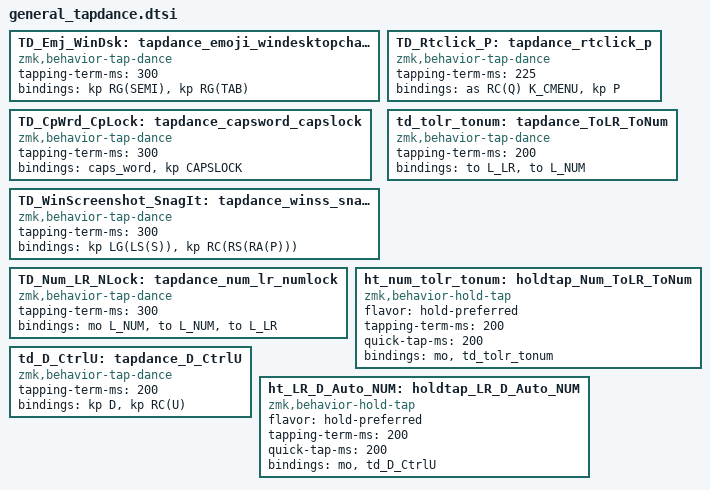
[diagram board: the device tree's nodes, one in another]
/*****************************************************************************************************
 *  TAP DANCE configurations
 *  for general cases
 *  [ ] macro-ify?
 *****************************************************************************************************/
#include <dt-bindings/zmk/keys.h>

// INCLUDE THIS inside Behaviors section of Keymap where other dependencies already pre-included

// 2024-04-16: label removed from ZMK v3

TD_Emj_WinDsk: tapdance_emoji_windesktopchange {
    compatible = "zmk,behavior-tap-dance";
    #binding-cells = <0>;
    tapping-term-ms = <300>;
    bindings = <&kp RG(SEMI)>, <&kp RG(TAB)>; // [1x] Win+; (Emoji pop-up)    [2x] Win+Tab (Windows desktops)
};

TD_CpWrd_CpLock: tapdance_capsword_capslock {
    compatible = "zmk,behavior-tap-dance";
    #binding-cells = <0>;
    tapping-term-ms = <300>;
    bindings = <&caps_word>, <&kp CAPSLOCK>;
};

/* Home/End: 2024-04-21 replaced with Hold/Tap instead of 2x-tap
TD_Hm_CtrlHm: tapdance_home_ctrlhome {
    compatible = "zmk,behavior-tap-dance";
    #binding-cells = <0>;
    tapping-term-ms = <300>;
    bindings = <&kp HOME>, <&kp RC(HOME)>;
};

TD_En_CtrlEn: tapdance_end_ctrlend {
    compatible = "zmk,behavior-tap-dance";
    #binding-cells = <0>;
    tapping-term-ms = <300>;
    bindings = <&kp END>, <&kp RC(END)>;
};
*/

TD_WinScreenshot_SnagIt: tapdance_winss_snagitss {
    compatible = "zmk,behavior-tap-dance";
    #binding-cells = <0>;
    tapping-term-ms = <300>;
    bindings = <&kp LG(LS(S))>, <&kp RC(RS(RA(P)))>;  // [1x] Win+Shift+S   [2x] Ctrl+Shift+Alt+P (customized in SnagIt settings)
};

// goal: 1x tap = BKSP, Hold = Ctl(bksp), 2x-tap-hold = repeat-backspace (see use with &as)
// idea: 2x-tap skips over the Hold behavior the &as would have caused.
// 2024-04-21: WIP, not in use yet; not right combo-syntax for the layout.
// 2024-04-21: an auto-shift with deliberate tapping-term &c works - see layout
// TD_BkspHoldTap: tapdance_bksp_holdtap {
//     compatible = "zmk,behavior-tap-dance";
//     #binding-cells = <0>;
//     tapping-term-ms = <300>;
//     bindings = <&as_slw RC(BSPC) BSPC>, <&kp BKSP>;
// };

// 2024-07-23 special for 2x-tap 'Menu-key' to add "P" [for OneNote when rt-click on a paragraph; to get link to paragraph]
// 1st-tap is an AutoShift(hold) case - SO...
// 1-tap: rt-click menu; 2-tap: "P"; Hold: Ctrl+Q
TD_Rtclick_P: tapdance_rtclick_p {
    compatible = "zmk,behavior-tap-dance";
    #binding-cells = <0>;
    tapping-term-ms = <225>; // 150 too fast, 300 too slow?
    bindings = <&as RC(Q) K_CMENU>, <&kp P>; 
};



// PRIOR one trying to replace [think Ø need / clean up later]
TD_Num_LR_NLock: tapdance_num_lr_numlock {
    compatible = "zmk,behavior-tap-dance";
    #binding-cells = <0>;
    tapping-term-ms = <300>;
    bindings = <&mo L_NUM>, <&to L_NUM>, <&to L_LR>; // [hold] Num   [2x] to NUM  [3x] to LR
};


// **************************************************
// goal: hold = NUM; [1x] >NUM; [2x] >LR
// TRY 4: tap-dance for &to <layer-first-tap>; &to <layer-2nd-tap>
// ref: https://www.reddit.com/r/zmk/comments/1ajmjl6/tapdance_with_nested_mt_leads_to_delay_until/
// think all terms-ms need to match?
// NOTE: HT always takes 2 args / so use like "ht_num_tonum_tolr L_NUM 0"
// NOTE: need 'plain' parms for hold-tap; so pass in the NUM layer in keymap not here: "<&mo>" here not "<&mo LAYER>" ==> then in keymap: "&macro LNUM 0"

td_tolr_tonum: tapdance_ToLR_ToNum {
    compatible = "zmk,behavior-tap-dance";
    #binding-cells = <0>;
    tapping-term-ms = <200>;
    bindings = <&to L_LR>, <&to L_NUM>; // 1st tap to 1st layer, 2x tap to 2nd layer
};

ht_num_tolr_tonum: holdtap_Num_ToLR_ToNum {
    compatible = "zmk,behavior-hold-tap";
    #binding-cells = <2>;
    flavor = "hold-preferred"; // which?
    tapping-term-ms = <200>;
    quick-tap-ms = <200>;
    bindings = <&mo>, <&td_tolr_tonum>;
    //retro-tap; // need this?
    // 2024-08-26 changed to "hold-preferred" and removed "retro-tap" / then worked / Ø sure if needed both
};

// similar as above but for D and Lightroom: Hold=NUM, Tap=D, 2-Tap=(Ctrl+U)
td_D_CtrlU: tapdance_D_CtrlU {
    compatible = "zmk,behavior-tap-dance";
    #binding-cells = <0>;
    tapping-term-ms = <200>;
    bindings = <&kp D>, <&kp RC(U)>; // 1st tap - D (LR: develop), 2x tap - Ctrl+U (LR: auto-develop settings)
};

ht_LR_D_Auto_NUM: holdtap_LR_D_Auto_NUM {
    compatible = "zmk,behavior-hold-tap";
    #binding-cells = <2>;
    flavor = "hold-preferred"; // which?
    tapping-term-ms = <200>;
    quick-tap-ms = <200>;
    bindings = <&mo>, <&td_D_CtrlU>;
};

